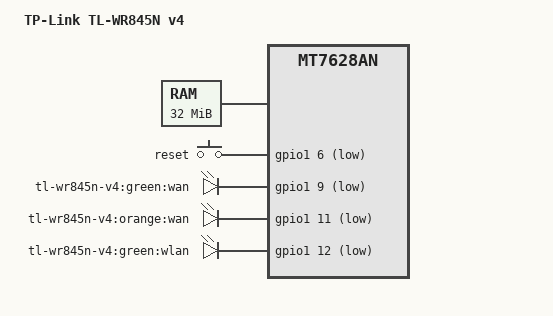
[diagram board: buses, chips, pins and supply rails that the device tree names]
/dts-v1/;

#include "TPLINK-4M.dtsi"

#include <dt-bindings/gpio/gpio.h>
#include <dt-bindings/input/input.h>

/ {
	compatible = "tplink,tl-wr845n-v4", "mediatek,mt7628an-soc";
	model = "TP-Link TL-WR845N v4";

	aliases {
		led-boot = &led_power_green;
		led-failsafe = &led_power_green;
		led-running = &led_power_green;
		led-upgrade = &led_power_green;
	};

	memory@0 {
		device_type = "memory";
		reg = <0x0 0x2000000>;
	};

 	gpio-keys-polled {
		compatible = "gpio-keys-polled";
		#address-cells = <1>;
		#size-cells = <0>;
		poll-interval = <20>;
 		reset {
			label = "reset";
			gpios = <&gpio1 6 GPIO_ACTIVE_LOW>;
			linux,code = <KEY_RESTART>;
		};
	};
	/* LED used is dual-color,dual lead LED */
	gpio-leds {
		compatible = "gpio-leds";

 		led_power_green: wan_green {
			label = "tl-wr845n-v4:green:wan";
			gpios = <&gpio1 9 GPIO_ACTIVE_LOW>;
		};
 		wan_orange {
			label = "tl-wr845n-v4:orange:wan";
			gpios = <&gpio1 11 GPIO_ACTIVE_LOW>;
		};
 		wlan {
			label = "tl-wr845n-v4:green:wlan";
			gpios = <&gpio1 12 GPIO_ACTIVE_LOW>;
		};
	};
};

&pinctrl {
	state_default: pinctrl0 {
		gpio {
			ralink,group = "p0led_an", "p1led_an", "p2led_an", "perst", "wled_an";
			ralink,function = "gpio";
		};
	};
};
